# MB9AF31xM register map
File version: 1.8
CPU: 
Registers are 8-bit, read-write, reset 0x0 unless marked. A register's access mark holds for its fields unless they carry their own. Offsets are from the block's base; [hi:lo] are bit positions; {n}, {i} and the like mark numbered series.

## QPRC0 — Quadrature Position/Revolution Counter 0
Base 0x40026000
Same registers: QPRC1 0x40026040
0x00 QPCR 16-bit — QPRC Position Count Register
0x04 QRCR 16-bit — QPRC Revolution Count Register
0x08 QPCCR 16-bit — QPRC Position Counter Compare Register
0x0C QPRCR 16-bit — QPRC Position and Revolution Counter Compare Register
0x10 QMPR 16-bit reset 0xFFFF — QPRC Maximum Position Register
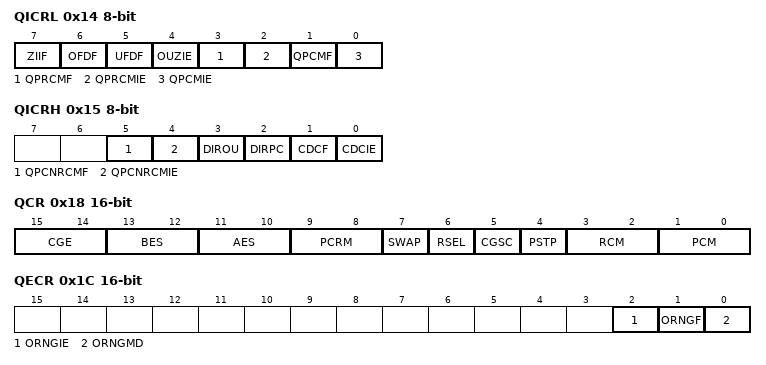
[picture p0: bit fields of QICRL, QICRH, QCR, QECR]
0x14 QICRL — Low-Order Bytes of QPRC Interrupt Control Register
  [7] ZIIF — Zero index interrupt request flag bit
  [6] OFDF — Overflow interrupt request flag bit
  [5] UFDF — Underflow interrupt request flag bit
  [4] OUZIE — "Overflow, underflow, or zero index interrupt enable bit"
  [3] QPRCMF — PC and RC match interrupt request flag bit
  [2] QPRCMIE — PC and RC match interrupt enable bit
  [1] QPCMF — PC match interrupt request flag bit
  [0] QPCMIE — PC match interrupt enable bit
0x15 QICRH — High-Order Bytes of QPRC Interrupt Control Register
  [5] QPCNRCMF — PC match and RC match interrupt request flag bit
  [4] QPCNRCMIE — PC match and RC match interrupt enable bit
  [3] DIROU ro — Last position counter flow direction bit
  [2] DIRPC ro — Last position counter direction bit
  [1] CDCF — Count inversion interrupt request flag bit
  [0] CDCIE — Count inversion interrupt enable bit
0x18 QCR 16-bit — QPRC Control Register
  [15:14] CGE — Detection edge selection bits
  [13:12] BES — BIN detection edge selection bits
  [11:10] AES — AIN detection edge selection bits
  [9:8] PCRM — Position counter reset mask bits
  [7] SWAP — Swap bit
  [6] RSEL — Register function selection bit
  [5] CGSC — Count clear or gate selection bit
  [4] PSTP — Position counter stop bit
  [3:2] RCM — Revolution counter mode bits
  [1:0] PCM — Position counter mode bits
0x1C QECR 16-bit — QPRC Extension Control Register
  [2] ORNGIE — Outrange interrupt enable bit
  [1] ORNGF — Outrange interrupt request flag bit
  [0] ORNGMD — Outrange mode selection bit

## WC — Watch Counter
Base 0x4003A000
0x00 WCRD ro — Watch Counter Read Register
  [5:0] CTR — counter value
0x01 WCRL — Watch Counter Reload Register
  [5:0] RLC — reload value
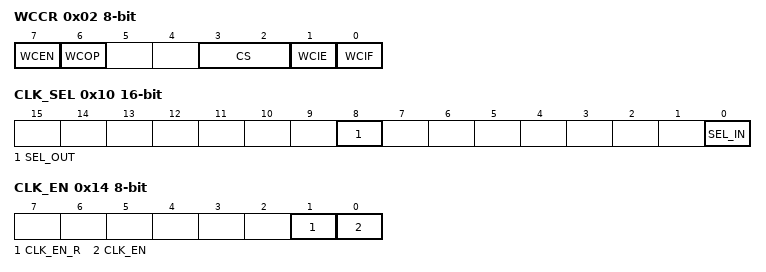
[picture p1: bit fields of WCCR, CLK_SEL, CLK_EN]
0x02 WCCR — Watch Counter Control Register
  [7] WCEN — Watch counter operation enable bit
  [6] WCOP ro — Watch counter operating state flag
  [3:2] CS — Count clock select bits
  [1] WCIE — Interrupt request enable bit
  [0] WCIF — Interrupt request flag bit
0x10 CLK_SEL 16-bit — Clock Selection Register
  [8] SEL_OUT — Output clock selection bit
  [0] SEL_IN — Input clock selection bit
0x14 CLK_EN — Division Clock Enable Register
  [1] CLK_EN_R — Division clock enable read bit
  [0] CLK_EN — Division clock enable bit

## EXTI — External Interrupt and NMI Control
Base 0x40030000
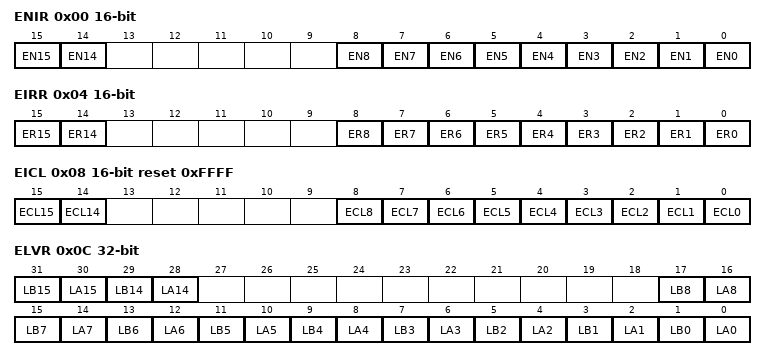
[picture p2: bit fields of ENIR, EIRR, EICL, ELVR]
0x00 ENIR 16-bit — Enable Interrupt Request Register
  [15] EN15 — Bit15 of ENIR
  [14] EN14 — Bit14 of ENIR
  [n] EN{n} (n=0..8) — Bit{n} of ENIR
0x04 EIRR 16-bit ro reset not defined — External Interrupt Request Register
  [15] ER15 — Bit15 of EIRR
  [14] ER14 — Bit14 of EIRR
  [n] ER{n} (n=0..8) — Bit{n} of EIRR
0x08 EICL 16-bit reset 0xFFFF — External Interrupt Clear Register
  [15] ECL15 — Bit15 of EICL
  [14] ECL14 — Bit14 of EICL
  [n] ECL{n} (n=0..8) — Bit{n} of EICL
0x0C ELVR 32-bit — External Interrupt Level Register
  [31] LB15 — Bit31 of ELVR
  [30] LA15 — Bit30 of ELVR
  [29] LB14 — Bit29 of ELVR
  [28] LA14 — Bit28 of ELVR
  [2n+1] LB{n} (n=0..8) — Bit{2n+1} of ELVR
  [2n] LA{n} (n=0..8) — Bit{2n} of ELVR
0x14 NMIRR ro — Non Maskable Interrupt Request Register
  [0] NR — NMI interrupt request detection bit
0x18 NMICL reset 0x1 — Non Maskable Interrupt Clear Register
  [0] NCL — NMI interrupt cause clear bit

## LVD — Low-voltage Detection
Base 0x40035000
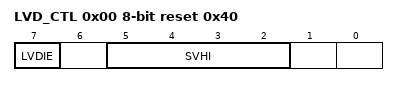
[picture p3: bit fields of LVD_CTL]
0x00 LVD_CTL reset 0x40 — Low-voltage Detection Voltage Control Register
  [7] LVDIE — Low-voltage detection interrupt enable bit
  [5:2] SVHI — Low-voltage detection interrupt voltage setting bits
0x04 LVD_STR ro — Low-voltage Detection Interrupt Register
  [7] LVDIR — Low-voltage detection interrupt bit
0x08 LVD_CLR reset 0x80 — Low-voltage Detection Interrupt Clear Register
  [7] LVDCL — Low-voltage detection interrupt clear bit
0x0C LVD_RLR 32-bit reset 0x1 — Low-voltage Detection Voltage Protection Register
  [31:0] LVDLCK — Low-voltage Detection Voltage Control Register protection bits
0x10 LVD_STR2 ro reset 0x40 — Low-voltage Detection Circuit Status Register
  [7] LVDIRDY — Low-voltage detection interrupt status flag
